# RL7005_IP_SVD register map
Vendor: Realtek
Registers are 32-bit, read-write, reset 0x0 unless marked. A register's access mark holds for its fields unless they carry their own. Offsets are from the block's base; [hi:lo] are bit positions; <NAME> marks a mode.

## IR_REG
Base 0x41007000
0x00 IR_CLK_DIV — IR clock division register
  [11:0] IR_CLK_DIV — IR_CLK = IO_CLK/(1 + IR_CLK_DIV) *Tx mode: divider number to generate IrDA modulation frequency. For example: sys_clk = 100MHz, modulation_freq = 455kHz, IR_DIV_NUM = (sys_clk/modulation_freq) - 1 *Rx mode: waveform sample clock. IR_DIV_NUM = (sys_clk/sample clock) - 1 For example: sample clock = 100MHz, IR_DIV_NUM = 0; sample clock = 50MHz, IR_DIV_NUM = 1
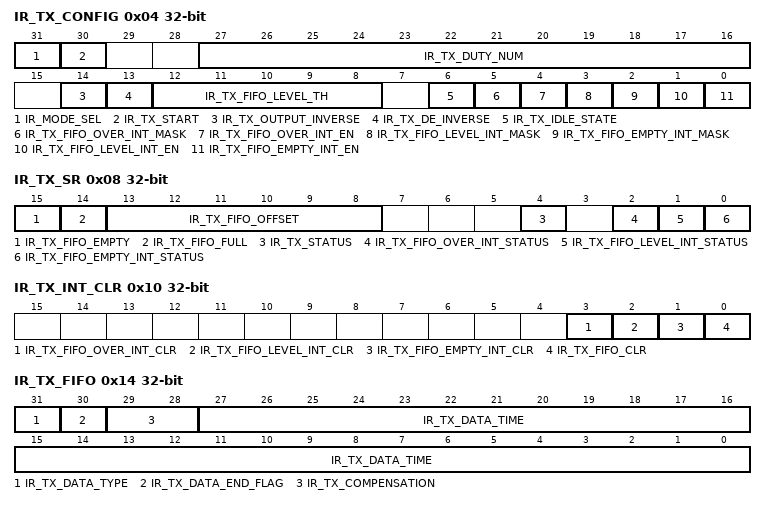
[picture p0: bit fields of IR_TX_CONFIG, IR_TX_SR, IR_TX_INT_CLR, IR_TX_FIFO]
0x04 IR_TX_CONFIG — IR Tx configuration register
  [31] IR_MODE_SEL — *0: Tx mode *1: Rx mode
  [30] IR_TX_START — *0: FSM stops at idle state. *1: FSM runs.
  [27:16] IR_TX_DUTY_NUM — Duty cycle setting for modulation frequency For example: for 1/3 duty cycle, IR_DUTY_NUM = (IR_DIV_NUM+1)/3 Note: Set this value equals to IR_DIV_NUM to generate 100% duty waveform.
  [14] IR_TX_OUTPUT_INVERSE — *0: Not inverse active output *1: Inverse active output
  [13] IR_TX_DE_INVERSE — *0: Not inverse FIFO define *1: Inverse FIFO define
  [12:8] IR_TX_FIFO_LEVEL_TH — Tx FIFO interrupt threshold. When Tx FIFO depth = < threshold value, interrupt is triggered.
  [6] IR_TX_IDLE_STATE — Tx output state in idle *0: Low *1: High
  [5] IR_TX_FIFO_OVER_INT_MASK — Tx FIFO overflow interrupt *0: Unmask *1: Mask
  [4] IR_TX_FIFO_OVER_INT_EN — Tx FIFO overflow interrupt *0: Disable *1: Enable
  [3] IR_TX_FIFO_LEVEL_INT_MASK — Tx FIFO level interrupt *0: Unmask *1: Mask
  [2] IR_TX_FIFO_EMPTY_INT_MASK — Tx FIFO empty interrupt *0: Unmask *1: Mask
  [1] IR_TX_FIFO_LEVEL_INT_EN — Tx FIFO level interrupt When Tx FIFO offset <= threshold value, interrupt is triggered. *0: Disable *1: Enable
  [0] IR_TX_FIFO_EMPTY_INT_EN — Tx FIFO empty interrupt *0: Disable *1: Enable
0x08 IR_TX_SR ro — IR Tx FIFO and interrupt status register
  [15] IR_TX_FIFO_EMPTY — *0: Not empty *1: Empty
  [14] IR_TX_FIFO_FULL — *0: Not full *1: Full
  [13:8] IR_TX_FIFO_OFFSET — Tx FIFO offset is from 0 to 32. Note: After Tx last packet, hardware can't clear Tx FIFO offset.
  [4] IR_TX_STATUS — *0: Idle *1: Run
  [2] IR_TX_FIFO_OVER_INT_STATUS — Tx FIFO overflow interrupt *0: Interrupt inactive *1: Interrupt active
  [1] IR_TX_FIFO_LEVEL_INT_STATUS — When Tx FIFO offset <= threshold value, interrupt is triggered. *0: Interrupt inactive *1: Interrupt active
  [0] IR_TX_FIFO_EMPTY_INT_STATUS — Tx FIFO empty interrupt *0: Interrupt inactive *1: Interrupt active
0x0C IR_TX_COMPE_DIV — IR Tx compensation division register
  [11:0] TX_COMPE_DIV — IR_TX_CLK_Period = SCLK/(TX_COMPE_DIV + 1)
0x10 IR_TX_INT_CLR wo — IR Tx FIFO and interrupt clear register
  [3] IR_TX_FIFO_OVER_INT_CLR — Tx FIFO overflow interrupt Write 1 to clear
  [2] IR_TX_FIFO_LEVEL_INT_CLR — When Tx FIFO offset <= threshold value, interrupt is triggered. Write 1 to clear
  [1] IR_TX_FIFO_EMPTY_INT_CLR — Tx FIFO empty interrupt Write 1 to clear
  [0] IR_TX_FIFO_CLR — Write 1 to clear Tx FIFO
0x14 IR_TX_FIFO wo
  [31] IR_TX_DATA_TYPE — Data type *0: Inactive carrier (no carrier) *1: Active carrier (carrier)
  [30] IR_TX_DATA_END_FLAG — *0: Normal packet *1: Last packet
  [29:28] IR_TX_COMPENSATION — *0x0: IR_TX_CLK_Period = Tsys_clk * IR_CLK_DIV *0x1: IR_TX_CLK_Period = (1 + 1/2) Tsys_clk * IR_CLK_DIV *0x2: IR_TX_CLK_Period = (1 + 1/4) Tsys_clk * IR_CLK_DIV *0x3: IR_TX_CLK_Period = Tsys_clk * (IR_TX_COMPE_DIV + 1)
  [27:0] IR_TX_DATA_TIME — Real active time = (IR_TX_DATA_TIME + 1) * IR_TX_CLK_Period
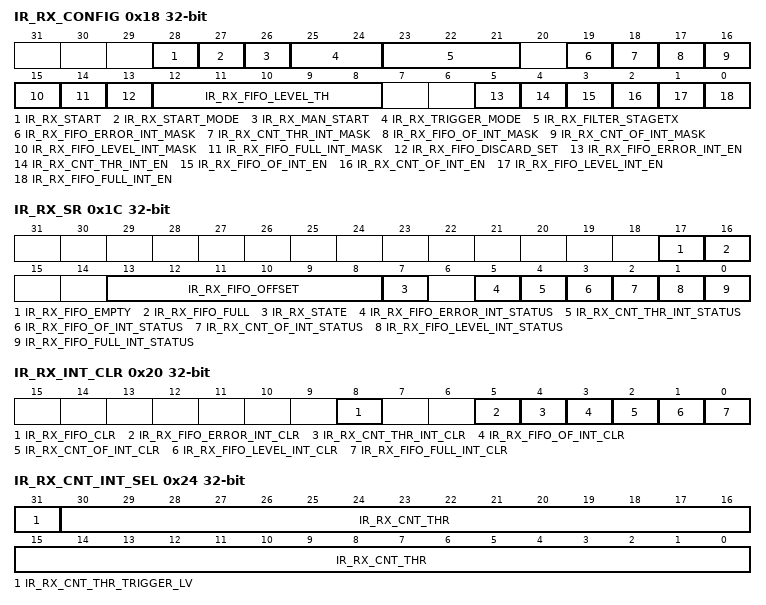
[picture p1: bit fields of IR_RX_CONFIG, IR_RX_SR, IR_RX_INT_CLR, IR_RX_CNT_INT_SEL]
0x18 IR_RX_CONFIG — IR Rx configuration register
  [28] IR_RX_START — *0: FSM stops at idle state. *1: FSM runs.
  [27] IR_RX_START_MODE — *0: Manual mode, IR_RX_MAN_START control *1: Auto-mode, Trigger-mode cont
  [26] IR_RX_MAN_START — If IR_RX_TRIGGER_MODE =0, writing 1 means starting to check the waveform.
  [25:24] IR_RX_TRIGGER_MODE — *00: High --> low trigger *01: Low -> high trigger *10: High -> low or low ->high trigger
  [23:21] IR_RX_FILTER_STAGETX — *0x0: Filter <= 20ns glitch *0x1: Filter <= 30ns glitch *0x2: Filter <= 40ns glitch *0x3: Filter <= 50ns glitch ...
  [19] IR_RX_FIFO_ERROR_INT_MASK — Rx FIFO error read interrupt When Rx FIFO is empty, read Rx FIFO and trigger interrupt. *0: Unmask *1: Mask
  [18] IR_RX_CNT_THR_INT_MASK — Rx count threshold interrupt *0: Unmask *1: Mask
  [17] IR_RX_FIFO_OF_INT_MASK — Rx FIFO overflow *0: Unmask *1: Mask
  [16] IR_RX_CNT_OF_INT_MASK — RX counter overflow *0: Unmask *1: Mask
  [15] IR_RX_FIFO_LEVEL_INT_MASK — Rx FIFO level interrupt *0: Unmask *1: Mask When Rx FIFO offset >= threshold value, this interrupt is triggered.
  [14] IR_RX_FIFO_FULL_INT_MASK — Rx FIFO full interrupt *0: Unmask *1: Mask
  [13] IR_RX_FIFO_DISCARD_SET — When FIFO is full, new data is send to FIFO. *0: Discard oldest data in FIFO. *1: Reject new data sending to FIFO.
  [12:8] IR_RX_FIFO_LEVEL_TH — Rx FIFO interrupt threshold When Rx FIFO depth > threshold value, this interrupt is triggered.
  [5] IR_RX_FIFO_ERROR_INT_EN — Rx FIFO error read interrupt When Rx FIFO is empty, reading the Rx FIFO triggers this interrupt. *0: Disable *1: Enable
  [4] IR_RX_CNT_THR_INT_EN — Rx count threshold interrupt *0: Disable *1: Enable
  [3] IR_RX_FIFO_OF_INT_EN — RX FIFO overflow *0: Disable *1: Enable
  [2] IR_RX_CNT_OF_INT_EN — RX counter overflow *0: Disable *1: Enable
  [1] IR_RX_FIFO_LEVEL_INT_EN — Rx FIFO level interrupt When Rx FIFO offset >= threshold value, this interrupt is triggered. *0: Disable *1: Enable
  [0] IR_RX_FIFO_FULL_INT_EN — Rx FIFO full interrupt *0: Disable *1: Enable
0x1C IR_RX_SR ro — IR Rx FIFO and interrupt status register
  [17] IR_RX_FIFO_EMPTY — *0: Not empty *1: Empty
  [16] IR_RX_FIFO_FULL — *0: Not full *1: Full
  [13:8] IR_RX_FIFO_OFFSET — Rx FIFO offset
  [7] IR_RX_STATE — *0: Idle *1: Run
  [5] IR_RX_FIFO_ERROR_INT_STATUS — Rx FIFO error read interrupt status When Rx FIFO is empty, reading the Rx FIFO triggers this interrupt. *0: Interrupt is inactive *1: Interrupt is active
  [4] IR_RX_CNT_THR_INT_STATUS — Rx count threshold interrupt status *0: Interrupt is inactive *1: Interrupt is active
  [3] IR_RX_FIFO_OF_INT_STATUS — Rx FIFO overflow interrupt status *0: Interrupt is inactive *1: Interrupt is active
  [2] IR_RX_CNT_OF_INT_STATUS — Rx counter overflow interrupt status *0: Interrupt is inactive *1: Interrupt is active
  [1] IR_RX_FIFO_LEVEL_INT_STATUS — Rx FIFO level interrupt status *0: Interrupt is inactive *1: Interrupt is active
  [0] IR_RX_FIFO_FULL_INT_STATUS — Rx FIFO full interrupt status *0: Interrupt is inactive *1: Interrupt is active
0x20 IR_RX_INT_CLR wo — IR Rx FIFO and interrupt clear register
  [8] IR_RX_FIFO_CLR — Write 1 to clear Rx FIFO
  [5] IR_RX_FIFO_ERROR_INT_CLR — Rx FIFO error read interrupt Write 1 to clear
  [4] IR_RX_CNT_THR_INT_CLR — Rx count threshold interrupt Write 1 to clear
  [3] IR_RX_FIFO_OF_INT_CLR — Rx FIFO overflow interrupt Write 1 to clear
  [2] IR_RX_CNT_OF_INT_CLR — Rx counter overflow interrupt Write 1 to clear
  [1] IR_RX_FIFO_LEVEL_INT_CLR — Rx FIFO level interrupt Write 1 to clear
  [0] IR_RX_FIFO_FULL_INT_CLR — Rx FIFO full interrupt Write 1 to clear
0x24 IR_RX_CNT_INT_SEL — IR Rx count threshold configure register
  [31] IR_RX_CNT_THR_TRIGGER_LV — Trigger level *0: When low level counter >= threshold, trigger interrupt *1: When high level counter >= threshold, trigger interrupt
  [30:0] IR_RX_CNT_THR — 31-bits threshold
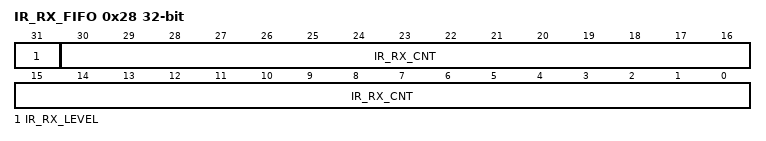
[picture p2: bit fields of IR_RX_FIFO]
0x28 IR_RX_FIFO ro
  [31] IR_RX_LEVEL — Rx Level *1: High level *0: Low level
  [30:0] IR_RX_CNT — 31-bits cycle duration
0x2C IR_VERSION ro reset 0x1410150A — IR IP version register
  [31:0] IR_VERSION — IR IP version
0x30 IR_DUMMY ro
  [15:0] dummy — rsvd for hw
